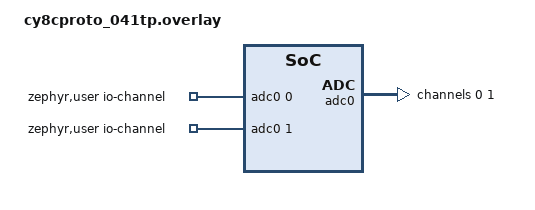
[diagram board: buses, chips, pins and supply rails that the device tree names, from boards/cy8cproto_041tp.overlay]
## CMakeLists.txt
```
# SPDX-License-Identifier: Apache-2.0

cmake_minimum_required(VERSION 3.28.0)

find_package(Zephyr REQUIRED HINTS $ENV{ZEPHYR_BASE})
project(adc_error_cases)

FILE(GLOB app_sources src/*.c)
target_sources(app PRIVATE ${app_sources})
```

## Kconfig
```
# SPDX-FileCopyrightText: Copyright (c) 2026 Infineon Technologies AG,
# SPDX-FileCopyrightText: or an affiliate of Infineon Technologies AG. All rights reserved.
#
# SPDX-License-Identifier: Apache-2.0

source "Kconfig.zephyr"

config TEST_ADC_ERROR_CASES_RESOLUTION
	int
	default 12 if SOC_FAMILY_SILABS_S2 || SOC_FAMILY_SILABS_S3 || SOC_SERIES_PSC3 || \
		SOC_SERIES_IT51XXX
	default 10
```

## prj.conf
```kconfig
CONFIG_ZTEST=y

CONFIG_ADC=y
```

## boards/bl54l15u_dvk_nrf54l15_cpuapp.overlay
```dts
/*
 * SPDX-License-Identifier: Apache-2.0
 *
 * Copyright (c) 2024 Nordic Semiconductor ASA
 * Copyright (c) 2025 Ezurio LLC
 */

/ {
	aliases {
		adc = &adc;
	};
};
```

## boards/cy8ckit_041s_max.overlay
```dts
/*
 * SPDX-FileCopyrightText: Copyright (c) 2026 Infineon Technologies AG,
 * SPDX-FileCopyrightText: or an affiliate of Infineon Technologies AG. All rights reserved.
 *
 * SPDX-License-Identifier: Apache-2.0
 */

#include <zephyr/dt-bindings/adc/adc.h>
#include <zephyr/dt-bindings/adc/infineon-sar.h>
#include <zephyr/dt-bindings/pinctrl/ifx_cat1-pinctrl.h>

/ {
	aliases {
		adc = &adc0;
	};

	zephyr,user {
		io-channels = <&adc0 0>;
	};
};

&pinctrl {
	p2_0_adc: p2_0_adc {
		pinmux = <DT_CAT1_PINMUX(2, 0, HSIOM_SEL_GPIO)>;
	};
};

&adc0 {
	vref-src = "internal";
	pinctrl-0 = <&p2_0_adc>;
	pinctrl-names = "default";
	#address-cells = <1>;
	#size-cells = <0>;
	status = "okay";

	channel@0 {
		reg = <0>;
		zephyr,gain = "ADC_GAIN_1";
		zephyr,reference = "ADC_REF_INTERNAL";
		zephyr,input-positive = <CY_SAR_ADDR_SARMUX_0>;
		zephyr,resolution = <12>;
		zephyr,acquisition-time = <ADC_ACQ_TIME_DEFAULT>;
	};
};
```

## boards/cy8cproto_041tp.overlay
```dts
/*
 * SPDX-FileCopyrightText: Copyright (c) 2026 Infineon Technologies AG,
 * SPDX-FileCopyrightText: or an affiliate of Infineon Technologies AG. All rights reserved.
 *
 * SPDX-License-Identifier: Apache-2.0
 */

/*
 * ADC Channel to GPIO Pin Mapping for Testing:
 *
 * Channel	ADC Pin	Routing Type	GPIO Pin	Test Pin (V+)	Test Pin (V-)
 * Channel 0	0	SARMUX		P2.0		P2.0		GND
 * Channel 1	2, 3	SARMUX (diff)	P2.2 (V+), P2.3 (V-)	P2.2	P2.3
 */

#include <zephyr/dt-bindings/adc/adc.h>
#include <zephyr/dt-bindings/adc/infineon-sar.h>
#include <zephyr/dt-bindings/pinctrl/ifx_cat1-pinctrl.h>

/ {
	aliases {
		adc = &adc0;
	};

	zephyr,user {
		io-channels = <&adc0 0>, <&adc0 1>;
	};
};

&pinctrl {
	p2_0_adc: p2_0_adc {
		pinmux = <DT_CAT1_PINMUX(2, 0, HSIOM_SEL_GPIO)>;
	};

	p2_2_adc: p2_2_adc {
		pinmux = <DT_CAT1_PINMUX(2, 2, HSIOM_SEL_GPIO)>;
	};

	p2_3_adc: p2_3_adc {
		pinmux = <DT_CAT1_PINMUX(2, 3, HSIOM_SEL_GPIO)>;
	};
};

&adc0 {
	clocks = <&peri_clk_div4>;
	pinctrl-0 = <&p2_0_adc &p2_2_adc &p2_3_adc>;
	pinctrl-names = "default";
	#address-cells = <1>;
	#size-cells = <0>;
	status = "okay";

	channel@0 {
		reg = <0>;
		zephyr,gain = "ADC_GAIN_1";
		zephyr,reference = "ADC_REF_INTERNAL";
		zephyr,input-positive = <CY_SAR_ADDR_SARMUX_0>;
		zephyr,resolution = <12>;
		zephyr,oversampling = <8>;
		zephyr,acquisition-time = <ADC_ACQ_TIME_DEFAULT>;
	};

	channel@1 {
		reg = <1>;
		zephyr,gain = "ADC_GAIN_1";
		zephyr,differential;
		zephyr,reference = "ADC_REF_INTERNAL";
		zephyr,input-positive = <CY_SAR_ADDR_SARMUX_2>;
		zephyr,input-negative = <CY_SAR_ADDR_SARMUX_3>;
		zephyr,resolution = <12>;
		zephyr,oversampling = <0>;
		zephyr,acquisition-time = <ADC_ACQ_TIME_DEFAULT>;
	};
};
```

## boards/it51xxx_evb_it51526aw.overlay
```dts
/*
 * Copyright (c) 2026 ITE Corporation. All Rights Reserved.
 *
 * SPDX-License-Identifier: Apache-2.0
 */

&adc0 {
	pinctrl-0 = <&adc0_ch0_gpi0_default>;
	pinctrl-names = "default";
	status = "okay";
};
```

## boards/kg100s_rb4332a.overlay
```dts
/*
 * Copyright (c) 2026 Martin Moya <martin.moya@focus.uy>
 *
 * SPDX-License-Identifier: Apache-2.0
 */

/ {
	aliases {
		adc = &adc0;
	};
};

&adc0 {
	#address-cells = <1>;
	#size-cells = <0>;
	status = "okay";
};
```

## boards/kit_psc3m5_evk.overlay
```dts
/*
 * SPDX-FileCopyrightText: Copyright (c) 2026 Infineon Technologies AG,
 * SPDX-FileCopyrightText: or an affiliate of Infineon Technologies AG. All rights reserved.
 *
 * SPDX-License-Identifier: Apache-2.0
 */

#include <zephyr/dt-bindings/adc/adc.h>

/ {
	aliases {
		adc = &adc0;
	};
};

&adc0 {
	#address-cells = <1>; /* child channels */
	#size-cells = <0>;

	channel@1 {
		reg = <1>;
		zephyr,acquisition-time = <ADC_ACQ_TIME_DEFAULT>;
		zephyr,gain = "ADC_GAIN_1";
		zephyr,reference = "ADC_REF_INTERNAL";
		zephyr,resolution = <12>;
	};

	channel@2 {
		reg = <2>;
		zephyr,acquisition-time = <ADC_ACQ_TIME_DEFAULT>;
		zephyr,gain = "ADC_GAIN_1";
		zephyr,reference = "ADC_REF_INTERNAL";
		zephyr,resolution = <12>;
	};
};
```

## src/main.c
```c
/*
 * Copyright (c) 2024, Nordic Semiconductor ASA
 *
 * SPDX-License-Identifier: Apache-2.0
 */

#include <zephyr/kernel.h>
#include <zephyr/device.h>
#include <zephyr/ztest.h>
#include <zephyr/drivers/adc.h>

static const struct device *dev_adc = DEVICE_DT_GET(DT_ALIAS(adc));
#define BUFFER_LEN 8
uint16_t m_sample_buffer[BUFFER_LEN];

static struct adc_channel_cfg valid_channel_cfg = {
	.gain = ADC_GAIN_1,
	.channel_id = 0,
	.reference = ADC_REF_INTERNAL,
	.acquisition_time = ADC_ACQ_TIME_DEFAULT,
	.differential = false,
	#ifdef CONFIG_ADC_CONFIGURABLE_INPUTS
	.input_positive = 1,
	#endif
};

static struct adc_sequence valid_seq = {
	.buffer = m_sample_buffer,
	.buffer_size = BUFFER_LEN * sizeof(uint16_t),
	.options = NULL,
	.resolution = 8,
	.oversampling = 0,
	.channels = 1,
};

/**
 * @brief test adc_read() with invalid oversampling value
 *
 * function should return -EINVAL
 */

ZTEST(adc_error_cases, test_adc_read_invalid_oversampling)
{
	int ret;

	adc_channel_setup(dev_adc, &valid_channel_cfg);

	struct adc_sequence invalid_seq = valid_seq;
	/* Set oversampling to invalid value */
	invalid_seq.oversampling = 99;

	ret = adc_read(dev_adc, &invalid_seq);

	zassert_true(
		ret == -EINVAL,
		"adc_read() should return -EINVAL,"
		" got unexpected value of %d",
		ret
	);
}

/**
 * @brief test adc_read() with invalid resolution value
 *
 * function should return -EINVAL
 */

ZTEST(adc_error_cases, test_adc_read_invalid_resolution)
{
	int ret;

	adc_channel_setup(dev_adc, &valid_channel_cfg);

	struct adc_sequence invalid_seq = valid_seq;
	/* Set resolution to invalid value */
	invalid_seq.resolution = 99;

	ret = adc_read(dev_adc, &invalid_seq);

	zassert_true(
		ret == -EINVAL,
		"adc_read() should return -EINVAL,"
		" got unexpected value of %d",
		ret
	);
}

/**
 * @brief test adc_read() with invalid channels value
 *
 * function should return -EINVAL
 */

ZTEST(adc_error_cases, test_adc_read_invalid_channels)
{
	int ret;

	adc_channel_setup(dev_adc, &valid_channel_cfg);

	struct adc_sequence invalid_seq = valid_seq;
	/* Set channels configuration to invalid value */
	invalid_seq.channels = 0;

	ret = adc_read(dev_adc, &invalid_seq);

	zassert_true(
		ret == -EINVAL,
		"adc_read() should return -EINVAL,"
		" got unexpected value of %d",
		ret
	);
}

/**
 * @brief test adc_read() with not configured channel
 *
 * function should return -EINVAL
 */

ZTEST(adc_error_cases, test_adc_read_not_configured_channel)
{
	int ret;

	adc_channel_setup(dev_adc, &valid_channel_cfg);

	struct adc_sequence invalid_seq = valid_seq;
	/* Set channels configuration to use not configured channel */
	invalid_seq.channels = 2;

	ret = adc_read(dev_adc, &invalid_seq);

	zassert_true(
		ret == -EINVAL,
		"adc_read() should return -EINVAL,"
		" got unexpected value of %d",
		ret
	);
}

/**
 * @brief test adc_read() with invalid buffer length
 *
 * function should return -ENOMEM
 */

ZTEST(adc_error_cases, test_adc_read_invalid_buffer)
{
	int ret;

	adc_channel_setup(dev_adc, &valid_channel_cfg);

	struct adc_sequence invalid_seq = valid_seq;
	/* set buffer size to 0 bytes */
	invalid_seq.buffer_size = 0;

	ret = adc_read(dev_adc, &invalid_seq);

	zassert_true(
		ret == -ENOMEM,
		"adc_read() should return -ENOMEM,"
		" got unexpected value of %d",
		ret
	);
}

/**
 * @brief test adc_channel_setup() with invalid reference value
 *
 * function should return -EINVAL
 */

ZTEST(adc_error_cases, test_adc_setup_invalid_reference)
{
	int ret;

	struct adc_channel_cfg invalid_channel_cfg = valid_channel_cfg;
	/* set invalid reference */
	invalid_channel_cfg.reference = 99;

	ret = adc_channel_setup(dev_adc, &invalid_channel_cfg);

	zassert_true(
		ret == -EINVAL,
		"adc_channel_setup() should return -EINVAL,"
		" got unexpected value of %d",
		ret
	);
}

/**
 * @brief test adc_read() with invalid gain value
 *
 * function should return -EINVAL
 */

ZTEST(adc_error_cases, test_adc_setup_invalid_gain)
{
	int ret;

	struct adc_channel_cfg invalid_channel_cfg = valid_channel_cfg;
	/* set invalid gain value */
	invalid_channel_cfg.gain = 99;
	ret = adc_channel_setup(dev_adc, &invalid_channel_cfg);
	zassert_true(
		ret == -EINVAL,
		"adc_channel_setup() should return -EINVAL,"
		" got unexpected value of %d",
		ret
	);
}

/**
 * @brief test adc_read() with invalid acquisition time
 *
 * function should return -EINVAL
 */

ZTEST(adc_error_cases, test_adc_setup_invalid_acquisition_time)
{
	int ret;

	struct adc_channel_cfg invalid_channel_cfg = valid_channel_cfg;
	/* set invalid acquisition_time value */
	invalid_channel_cfg.acquisition_time = 16384;

	ret = adc_channel_setup(dev_adc, &invalid_channel_cfg);

	zassert_true(
		ret == -EINVAL,
		"adc_channel_setup() should return -EINVAL,"
		" got unexpected value of %d",
		ret
	);
}

static void *suite_setup(void)
{
	TC_PRINT("Test executed on %s\n", CONFIG_BOARD_TARGET);
	TC_PRINT("===================================================================\n");

	return NULL;
}

ZTEST_SUITE(adc_error_cases, NULL, suite_setup, NULL, NULL, NULL);
```

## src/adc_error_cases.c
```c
/*
 * Copyright (c) 2024, Nordic Semiconductor ASA
 *
 * SPDX-License-Identifier: Apache-2.0
 */

#include <zephyr/kernel.h>
#include <zephyr/device.h>
#include <zephyr/ztest.h>
#include <zephyr/drivers/adc.h>

static const struct device *dev_adc = DEVICE_DT_GET(DT_ALIAS(adc));
#define BUFFER_LEN 8
static uint16_t m_sample_buffer[BUFFER_LEN];

static const struct adc_channel_cfg valid_channel_cfg = {
	.gain = ADC_GAIN_1,
	.channel_id = 0,
	.reference = ADC_REF_INTERNAL,
	.acquisition_time = ADC_ACQ_TIME_DEFAULT,
	.differential = false,
	#ifdef CONFIG_ADC_CONFIGURABLE_INPUTS
	.input_positive = 1,
	#endif
};

#define VALID_RESOLUTION CONFIG_TEST_ADC_ERROR_CASES_RESOLUTION

static const struct adc_sequence valid_seq = {
	.buffer = m_sample_buffer,
	.buffer_size = BUFFER_LEN * sizeof(m_sample_buffer),
	.options = NULL,
	.resolution = VALID_RESOLUTION,
	.oversampling = 0,
	.channels = 1,
};

/**
 * @brief test adc_read() with invalid oversampling value
 *
 * function should return -EINVAL
 */

ZTEST(adc_error_cases, test_adc_read_invalid_oversampling)
{
	int ret;

	adc_channel_setup(dev_adc, &valid_channel_cfg);

	struct adc_sequence invalid_seq = valid_seq;
	/* Set oversampling to invalid value */
	invalid_seq.oversampling = 99;

	ret = adc_read(dev_adc, &invalid_seq);

	zassert_true(
		ret == -EINVAL,
		"adc_read() should return -EINVAL,"
		" got unexpected value of %d",
		ret
	);
}

/**
 * @brief test adc_read() with invalid resolution value
 *
 * function should return -EINVAL
 */

ZTEST(adc_error_cases, test_adc_read_invalid_resolution)
{
	int ret;

	adc_channel_setup(dev_adc, &valid_channel_cfg);

	struct adc_sequence invalid_seq = valid_seq;
	/* Set resolution to invalid value */
	invalid_seq.resolution = 99;

	ret = adc_read(dev_adc, &invalid_seq);

	zassert_true(
		ret == -EINVAL,
		"adc_read() should return -EINVAL,"
		" got unexpected value of %d",
		ret
	);
}

/**
 * @brief test adc_read() with invalid channels value
 *
 * function should return -EINVAL
 */

ZTEST(adc_error_cases, test_adc_read_invalid_channels)
{
	int ret;

	adc_channel_setup(dev_adc, &valid_channel_cfg);

	struct adc_sequence invalid_seq = valid_seq;
	/* Set channels configuration to invalid value */
	invalid_seq.channels = 0;

	ret = adc_read(dev_adc, &invalid_seq);

	zassert_true(
		ret == -EINVAL,
		"adc_read() should return -EINVAL,"
		" got unexpected value of %d",
		ret
	);
}

/**
 * @brief test adc_read() with not configured channel
 *
 * function should return -EINVAL
 */

ZTEST(adc_error_cases, test_adc_read_not_configured_channel)
{
	int ret;

	adc_channel_setup(dev_adc, &valid_channel_cfg);

	struct adc_sequence invalid_seq = valid_seq;
	/* Set channels configuration to use not configured channel */
	invalid_seq.channels = BIT(1);

	ret = adc_read(dev_adc, &invalid_seq);

	zassert_true(
		ret == -EINVAL,
		"adc_read() should return -EINVAL,"
		" got unexpected value of %d",
		ret
	);
}

/**
 * @brief test adc_read() with invalid buffer length
 *
 * function should return -ENOMEM
 */

ZTEST(adc_error_cases, test_adc_read_invalid_buffer)
{
	int ret;

	adc_channel_setup(dev_adc, &valid_channel_cfg);

	struct adc_sequence invalid_seq = valid_seq;
	/* set buffer size to 0 bytes */
	invalid_seq.buffer_size = 0;

	ret = adc_read(dev_adc, &invalid_seq);

	zassert_true(
		ret == -ENOMEM,
		"adc_read() should return -ENOMEM,"
		" got unexpected value of %d",
		ret
	);
}

/**
 * @brief test adc_channel_setup() with invalid reference value
 *
 * function should return -EINVAL
 */

ZTEST(adc_error_cases, test_adc_setup_invalid_reference)
{
	int ret;

	struct adc_channel_cfg invalid_channel_cfg = valid_channel_cfg;
	/* set invalid reference */
	invalid_channel_cfg.reference = 99;

	ret = adc_channel_setup(dev_adc, &invalid_channel_cfg);

	zassert_true(
		ret == -EINVAL,
		"adc_channel_setup() should return -EINVAL,"
		" got unexpected value of %d",
		ret
	);
}

/**
 * @brief test adc_read() with invalid gain value
 *
 * function should return -EINVAL
 */

ZTEST(adc_error_cases, test_adc_setup_invalid_gain)
{
	int ret;

	struct adc_channel_cfg invalid_channel_cfg = valid_channel_cfg;
	/* set invalid gain value */
	invalid_channel_cfg.gain = 99;
	ret = adc_channel_setup(dev_adc, &invalid_channel_cfg);
	zassert_true(
		ret == -EINVAL,
		"adc_channel_setup() should return -EINVAL,"
		" got unexpected value of %d",
		ret
	);
}

static void *suite_setup(void)
{
	TC_PRINT("Test executed on %s\n", CONFIG_BOARD_TARGET);
	TC_PRINT("===================================================================\n");

	return NULL;
}

ZTEST_SUITE(adc_error_cases, NULL, suite_setup, NULL, NULL, NULL);
```
